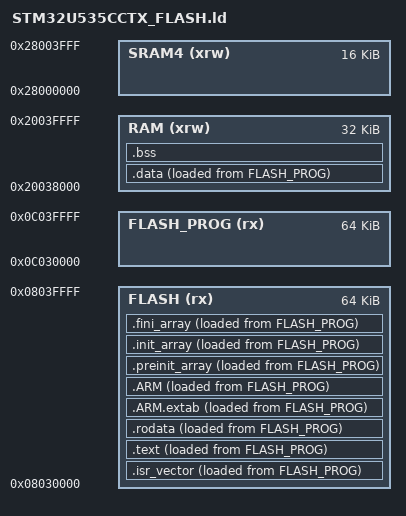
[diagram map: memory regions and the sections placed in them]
/*
******************************************************************************
**
**  File        : LinkerScript.ld
**
**  Author      : STM32CubeIDE
**
**  Abstract    : Linker script for STM32U535xC Device from STM32U5 series
**                      256Kbytes FLASH
**                      272Kbytes RAM
**
**                Set heap size, stack size and stack location according
**                to application requirements.
**
**                Set memory bank area and size if external memory is used.
**
**  Target      : STMicroelectronics STM32
**
**  Distribution: The file is distributed as is without any warranty
**                of any kind.
**
*****************************************************************************
** @attention
**
** Copyright (c) 2026 STMicroelectronics.
** All rights reserved.
**
** This software is licensed under terms that can be found in the LICENSE file
** in the root directory of this software component.
** If no LICENSE file comes with this software, it is provided AS-IS.
**
*****************************************************************************
*/

/* Entry Point */
ENTRY(Reset_Handler)

/* Highest address of the user mode stack */
_estack = ORIGIN(RAM) + LENGTH(RAM);	/* end of "RAM" Ram type memory */
_sstack = _estack - _Min_Stack_Size;

_Min_Heap_Size = 0x200;	/* USBX only */
_Min_Stack_Size = 0x400;

/* Memories definition */
MEMORY
{
  RAM	(xrw)	: ORIGIN = 0x20038000,	LENGTH = 32K     /* high 32K of SRAM2; low 32K is Secure */
  SRAM4	(xrw)	: ORIGIN = 0x28000000,	LENGTH = 16K
  /* CPU fetches the NS alias. CubeProgrammer's 0x08000000 map for this
   * device uses 16 KB sectors and erases the wrong pages, so the load
   * address is the secure alias of the same pages (8 KB sectors). */
  FLASH	(rx)	: ORIGIN = 0x08030000,	LENGTH = 64K
  FLASH_PROG (rx) : ORIGIN = 0x0C030000,	LENGTH = 64K
}

/* Sections */
SECTIONS
{
  /* The startup code into "FLASH" Rom type memory */
  .isr_vector :
  {
    KEEP(*(.isr_vector)) /* Startup code */
  } >FLASH AT> FLASH_PROG

  /* The program code and other data into "FLASH" Rom type memory */
  .text :
  {
    *(.text)           /* .text sections (code) */
    *(.text*)          /* .text* sections (code) */
    *(.glue_7)         /* glue arm to thumb code */
    *(.glue_7t)        /* glue thumb to arm code */
    *(.eh_frame)

    KEEP (*(.init))
    KEEP (*(.fini))

    . = ALIGN(4);
    _etext = .;        /* define a global symbols at end of code */
  } >FLASH AT> FLASH_PROG

  /* Constant data into "FLASH" Rom type memory */
  .rodata :
  {
    *(.rodata)         /* .rodata sections (constants, strings, etc.) */
    *(.rodata*)        /* .rodata* sections (constants, strings, etc.) */
    . = ALIGN(4);
  } >FLASH AT> FLASH_PROG

  .ARM.extab (READONLY) : /* The READONLY keyword is only supported in GCC11 and later, remove it if using GCC10 or earlier. */
  {
    *(.ARM.extab* .gnu.linkonce.armextab.*)
  } >FLASH AT> FLASH_PROG
  .ARM (READONLY) : /* The READONLY keyword is only supported in GCC11 and later, remove it if using GCC10 or earlier. */
  {
    __exidx_start = .;
    *(.ARM.exidx*)
    __exidx_end = .;
  } >FLASH AT> FLASH_PROG

  .preinit_array (READONLY) : /* The READONLY keyword is only supported in GCC11 and later, remove it if using GCC10 or earlier. */
  {
    PROVIDE_HIDDEN (__preinit_array_start = .);
    KEEP (*(.preinit_array*))
    PROVIDE_HIDDEN (__preinit_array_end = .);
  } >FLASH AT> FLASH_PROG

  .init_array (READONLY) : /* The READONLY keyword is only supported in GCC11 and later, remove it if using GCC10 or earlier. */
  {
    PROVIDE_HIDDEN (__init_array_start = .);
    KEEP (*(SORT(.init_array.*)))
    KEEP (*(.init_array*))
    PROVIDE_HIDDEN (__init_array_end = .);
  } >FLASH AT> FLASH_PROG

  .fini_array (READONLY) : /* The READONLY keyword is only supported in GCC11 and later, remove it if using GCC10 or earlier. */
  {
    PROVIDE_HIDDEN (__fini_array_start = .);
    KEEP (*(SORT(.fini_array.*)))
    KEEP (*(.fini_array*))
    PROVIDE_HIDDEN (__fini_array_end = .);
  } >FLASH AT> FLASH_PROG

  /* Startup runs NonSecure, so it must copy from the NS alias.
   * LOADADDR is the secure alias programmed by ST-Link. */
  _sidata = LOADADDR(.data) - 0x04000000;

  /* Initialized data sections into "RAM" Ram type memory */
  .data :
  {
    _sdata = .;        /* create a global symbol at data start */
    *(.data)           /* .data sections */
    *(.data*)          /* .data* sections */
    *(.RamFunc)        /* .RamFunc sections */
    *(.RamFunc*)       /* .RamFunc* sections */

    _edata = .;        /* define a global symbol at data end */
  } >RAM AT> FLASH_PROG

  /* Uninitialized data section into "RAM" Ram type memory */
  .bss :
  {
    /* This is used by the startup in order to initialize the .bss section */
    _sbss = .;         /* define a global symbol at bss start */
    __bss_start__ = _sbss;
    *(.bss)
    *(.bss*)
    *(COMMON)

    _ebss = .;         /* define a global symbol at bss end */
    __bss_end__ = _ebss;
    . = ALIGN(8);
    PROVIDE ( end = . );
    PROVIDE ( _end = . );
    . = . + _Min_Heap_Size;
    . = . + _Min_Stack_Size;
    . = ALIGN(8);
  } >RAM

  /* Remove information from the compiler libraries */
  /DISCARD/ :
  {
    libc.a ( * )
    libm.a ( * )
    libgcc.a ( * )
  }

  .ARM.attributes 0 : { *(.ARM.attributes) }
}
